# STM32H503 register map
File version: 1.5
CPU: CM33 r0p0, little endian, MPU, FPU, 4 interrupt priority bits
Registers are 32-bit, read-write, reset 0x0 unless marked. A register's access mark holds for its fields unless they carry their own. Offsets are from the block's base; [hi:lo] are bit positions; 'fields as' and 'values as' point back to an identical list.

## FLASH — FLASH address block description
Base 0x40022000
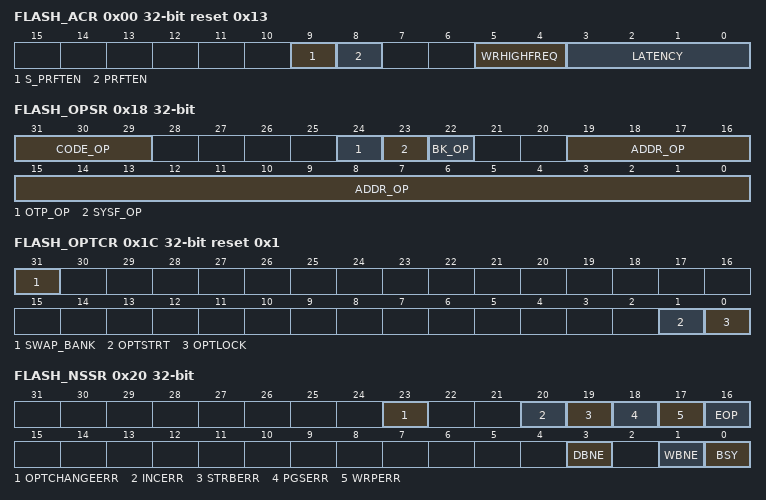
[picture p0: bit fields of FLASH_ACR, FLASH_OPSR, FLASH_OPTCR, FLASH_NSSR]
0x00 FLASH_ACR reset 0x13 — FLASH access control register
  [9] S_PRFTEN — Smart prefetch enable. When bit value is modified, user must read back ACR register to be sure S_PRFTEN has been taken into account. Bits used to control the prefetch functionality.
    0=prefetch, if enabled fetches each instruction; 1=prefetch, if enabled avoids fetch past branch to improve efficiency
  [8] PRFTEN — Prefetch enable. When bit value is modified, user must read back ACR register to be sure PRFTEN has been taken into account. Bits used to control the prefetch.
    0=prefetch disabled; 1=prefetch enabled when latency is at least one wait state
  [5:4] WRHIGHFREQ — Flash signal delay These bits are used to control the delay between non-volatile memory signals during programming operations. Application software has to program them to the correct value depending on the embedded Flash memory interface frequency. Please refer to for details. Note: No check is performed to verify that the configuration is correct. Two WRHIGHFREQ values can be selected for some frequencies.
  [3:0] LATENCY — Read latency These bits are used to control the number of wait states used during read operations on both non-volatile memory banks. The application software has to program them to the correct value depending on the embedded Flash memory interface frequency and voltage conditions. ... Note: No check is performed by hardware to verify that the configuration is correct.
    0=zero wait state used to read a word from non-volatile memory; 1=one wait state used to read a word from non-volatile memory; 2=two wait states used to read a word from non-volatile memory; 7=seven wait states used to read a word from non-volatile memory; 15=15 wait states used to read from non-volatile memory
0x04 FLASH_NSKEYR wo — FLASH key register
  [31:0] NSKEY — Non-volatile memory configuration access unlock key
0x0C FLASH_OPTKEYR wo — FLASH option key register
  [31:0] OPTKEY — FLASH option bytes control access unlock key
0x18 FLASH_OPSR ro reset not defined — FLASH operation status register
  [31:29] CODE_OP — Flash memory operation code
    0=No Flash operation on going during previous reset; 1=Single write operation interrupted; 3=Sector erase operation interrupted; 4=Bank erase operation interrupted; 5=Mass erase operation interrupted; 6=Option change operation interrupted
  [24] OTP_OP — OTP operation interrupted Indicates that reset interrupted an ongoing operation in OTP area.
  [23] SYSF_OP — Operation in system Flash memory interrupted Indicates that reset interrupted an ongoing operation in System Flash.
  [22] BK_OP — Interrupted operation bank It indicates which bank was concerned by operation.
  [19:0] ADDR_OP — Interrupted operation address.
0x1C FLASH_OPTCR access per field reset 0x1 (reset mask 0xFFFFFFF) — FLASH option control register
  [31] SWAP_BANK ro — Bank swapping option configuration bit SWAP_BANK controls whether Bank1 and Bank2 are swapped or not. This bit is loaded with the SWAP_BANK bit of FLASH_OPTSR_CUR register only after reset or POR.
    0=Bank1 and Bank2 not swapped; 1=Bank1 and Bank2 swapped
  [1] OPTSTRT rw — Option byte start change option configuration bit OPTSTRT triggers an option byte change operation. The user can set OPTSTRT only when the OPTLOCK bit is cleared to 0. It's set only by Software and cleared when the option byte change is completed or an error occurs (PGSERR or OPTCHANGEERR). It's reseted at the same time as BSY bit. The user application cannot modify any FLASH_XXX_PRG embedded Flash memory register until the option change operation has been completed. Before setting this bit, the user has to write the required values in the FLASH_XXX_PRG registers. The FLASH_XXX_PRG registers are locked until the option byte change operation has been executed in non-volatile memory.
  [0] OPTLOCK rw — FLASH_OPTCR lock option configuration bit The OPTLOCK bit locks the FLASH_OPTCR register as well as all _PRG registers. The correct write sequence to FLASH_OPTKEYR register unlocks this bit. If a wrong sequence is executed, or the unlock sequence to FLASH_OPTKEYR is performed twice, this bit remains locked until next system reset. It is possible to set OPTLOCK by programming it to 1. When set to 1, a new unlock sequence is mandatory to unlock it. When OPTLOCK changes from 0 to 1, the others bits of FLASH_OPTCR register do not change.
    0=FLASH_OPTCR register unlocked; 1=FLASH_OPTCR register locked
0x20 FLASH_NSSR ro (reset mask 0xFFFFFFF0) — FLASH non-secure status register
  [23] OPTCHANGEERR — Option byte change error flag OPTCHANGEERR flag indicates that an error occurred during an option byte change operation. When OPTCHANGEERR is set to 1, the option byte change operation did not successfully complete. An interrupt is generated when this flag is raised if the OPTCHANGEERRIE bit of FLASH_NSCR register is set to 1. Writing 1 to CLR_OPTCHANGEERR of register FLASH_CCR clears OPTCHANGEERR. Note: The OPTSTRT bit in FLASH_OPTCR cannot be set while OPTCHANGEERR is set.
    0=no option byte change errors occurred; 1=one or more errors occurred during an option byte change operation
  [20] INCERR — inconsistency error flag INCERR flag is raised when a inconsistency error occurs. An interrupt is generated if INCERRIE is set to 1. Writing 1 to CLR_INCERR bit in the FLASH_NSCCR register clears INCERR.
    0=no inconsistency error occurs; 1=a inconsistency error occurs
  [19] STRBERR — strobe error flag STRBERR flag is raised when a strobe error occurs (when the master attempts to write several times the same byte in the write buffer). An interrupt is generated if the STRBERRIE bit is set to 1. Writing 1 to CLR_STRBERR bit in FLASH_NSCCR register clears STRBERR.
    0=no strobe error occurred; 1=a strobe error occurred
  [18] PGSERR — programming sequence error flag PGSERR flag is raised when a sequence error occurs. An interrupt is generated if the PGSERRIE bit is set to 1. Writing 1 to CLR_PGSERR bit in FLASH_NSCCR register clears PGSERR.
    0=no sequence error occurred; 1=a sequence error occurred
  [17] WRPERR — write protection error flag WRPERR flag is raised when a protection error occurs during a program operation. An interrupt is also generated if the WRPERRIE is set to 1. Writing 1 to CLR_WRPERR bit in FLASH_NSCCR register clears WRPERR.
    0=no write protection error occurred; 1=a write protection error occurred
  [16] EOP — end of operation flag EOP flag is set when a operation (program/erase) completes. An interrupt is generated if the EOPIE is set to 1. It is not necessary to reset EOP before starting a new operation. EOP bit is cleared by writing 1 to CLR_EOP bit in FLASH_NSCCR register.
    0=no operation completed; 1=a operation completed
  [3] DBNE — data buffer not empty flag DBNE flag is set when the embedded Flash memory interface is processing 6-bits ECC data in dedicated buffer. This bit cannot be set to 0 by software. The hardware resets it once the buffer is free.
    0=data buffer not used; 1=data buffer used, wait
  [1] WBNE — write buffer not empty flag WBNE flag is set when the embedded Flash memory is waiting for new data to complete the write buffer. In this state, the write buffer is not empty. WBNE is reset by hardware each time the write buffer is complete or the write buffer is emptied following one of the event below: the application software forces the write operation using FW bit in FLASH_NSCR the embedded Flash memory detects an error that involves data loss This bit cannot be reset by software writing 0 directly. To reset it, clear the write buffer by performing any of the above listed actions, or send the missing data.
    0=write buffer empty or full; 1=write buffer waiting data to complete
  [0] BSY — busy flag BSY flag indicates that a Flash memory is busy by an operation (write, erase, option byte change). It is set at the beginning of a Flash memory operation and cleared when the operation finishes or an error occurs.
    0=no programming, erase or option byte change operation being executed; 1=programming, erase or option byte change operation being executed
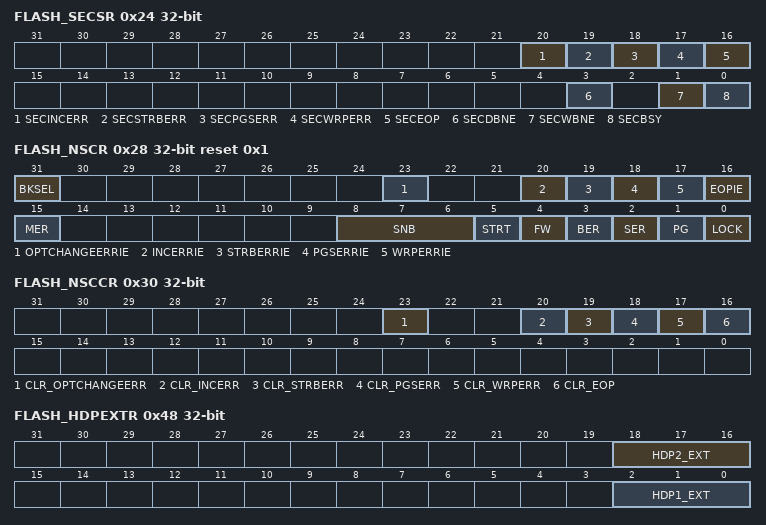
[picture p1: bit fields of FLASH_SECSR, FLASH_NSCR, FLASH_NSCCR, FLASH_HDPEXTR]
0x24 FLASH_SECSR ro (reset mask 0xFFFFFFF0) — FLASH secure status register
  [20] SECINCERR — inconsistency error flag INCERR flag is raised when a inconsistency error occurs. An interrupt is generated if INCERRIE is set to 1. Writing 1 to CLR_INCERR bit in the FLASH_SECCCR register clears INCERR.
    0=no inconsistency error occurred; 1=a inconsistency error occurred
  [19] SECSTRBERR — strobe error flag STRBERR flag is raised when a strobe error occurs (when the master attempts to write several times the same byte in the write buffer). An interrupt is generated if the STRBERRIE bit is set to 1. Writing 1 to CLR_STRBERR bit in FLASH_SECCCR register clears STRBERR.
    0=no strobe error occurred; 1=a strobe error occurred
  [18] SECPGSERR — programming sequence error flag PGSERR flag is raised when a sequence error occurs. An interrupt is generated if the PGSERRIE bit is set to 1. Writing 1 to CLR_PGSERR bit in FLASH_SECCCR register clears PGSERR.
    0=no sequence error occurred; 1=a sequence error occurred
  [17] SECWRPERR — write protection error flag WRPERR flag is raised when a protection error occurs during a program operation. An interrupt is also generated if the WRPERRIE is set to 1. Writing 1 to CLR_WRPERR bit in FLASH_SECCCR register clears WRPERR.
    values as FLASH_NSSR.WRPERR
  [16] SECEOP — end of operation flag EOP flag is set when a operation (program/erase) completes. An interrupt is generated if the EOPIE is set to. It is not necessary to reset EOP before starting a new operation. EOP bit is cleared by writing 1 to CLR_EOP bit in FLASH_SECCCR register.
    0=no operation completed; 1=a operation completed
  [3] SECDBNE — data buffer not empty flag DBNE flag is set when the embedded Flash memory interface is processing 6-bits ECC data in dedicated buffer. This bit cannot be set to 0 by software. The hardware resets it once the buffer is free.
    0=data buffer not used; 1=data buffer used, wait
  [1] SECWBNE — write buffer not empty flag WBNE flag is set when the embedded Flash memory is waiting for new data to complete the write buffer. In this state, the write buffer is not empty. WBNE is reset by hardware each time the write buffer is complete or the write buffer is emptied following one of the event below: the application software forces the write operation using FW bit in FLASH_SECCR the embedded Flash memory detects an error that involves data loss This bit cannot be reset by writing 0 directly by software. To reset it, clear the write buffer by performing any of the above listed actions, or send the missing data.
    values as FLASH_NSSR.WBNE
  [0] SECBSY — busy flag BSY flag indicates that a FLASH memory is busy by an operation (write, erase, option byte change, OBK operations, PUF operation). It is set at the beginning of a Flash memory operation and cleared when the operation finishes or an error occurs.
    values as FLASH_NSSR.BSY
0x28 FLASH_NSCR reset 0x1 — FLASH Non Secure control register
  [31] BKSEL — Bank selector bit BKSEL can only be programmed when LOCK is cleared to 0. The bit selects physical bank, SWAP_BANK setting is ignored.
    0=Bank1 is selected for Bank erase / sector erase / interrupt enable; 1=Bank2 is selected for BER / SER
  [23] OPTCHANGEERRIE — Option byte change error interrupt enable bit OPTCHANGEERRIE bit controls if an interrupt has to be generated when an error occurs during an option byte change. This bit can be programmed only when LOCK bit is cleared to 0.
    0=no interrupt is generated when an error occurs during an option byte change; 1=an interrupt is generated when and error occurs during an option byte change
  [20] INCERRIE — inconsistency error interrupt enable bit When INCERRIE bit is set to 1, an interrupt is generated when an inconsistency error occurs during a write operation. INCERRIE can be programmed only when LOCK is cleared to 0.
    0=no interrupt generated when a inconsistency error occurs; 1=interrupt generated when a inconsistency error occurs
  [19] STRBERRIE — strobe error interrupt enable bit When STRBERRIE bit is set to 1, an interrupt is generated when a strobe error occurs (the master programs several times the same byte in the write buffer) during a write operation. STRBERRIE can be programmed only when LOCK is cleared to 0.
    0=no interrupt generated when a strobe error occurs; 1=interrupt generated when strobe error occurs
  [18] PGSERRIE — programming sequence error interrupt enable bit When PGSERRIE bit is set to 1, an interrupt is generated when a sequence error occurs during a program operation. PGSERRIE can be programmed only when LOCK is cleared to 0.
    0=no interrupt generated when a sequence error occurs; 1=interrupt generated when sequence error occurs
  [17] WRPERRIE — write protection error interrupt enable bit When WRPERRIE bit is set to 1, an interrupt is generated when a protection error occurs during a program operation. WRPERRIE can be programmed only when LOCK is cleared to 0.
    0=no interrupt generated when a protection error occurs; 1=interrupt generated when a protection error occurs
  [16] EOPIE — end of operation interrupt control bit Setting EOPIE bit to 1 enables the generation of an interrupt at the end of a program or erase operation. EOPIE can be programmed only when LOCK is cleared to 0.
    0=no interrupt generated at the end of operation; 1=interrupt enabled when at the end of operation
  [15] MER — Mass erase request Setting MER bit to 1 requests a mass erase operation (user Flash memory only). MER can be programmed only when LOCK is cleared to 0. If BER or SER are both set, a PGSERR is raised. Error is triggered when a mass erase is required and some sectors are protected.
    0=mass erase not requested; 1=mass erase requested
  [8:6] SNB — sector erase selection number These bits are used to select the target sector for an erase operation (they are unused otherwise). SNB can be programmed only when LOCK is cleared to 0. ...
    0=Sector 0 selected; 1=Sector 1 selected; 7=Sector 7 selected
  [5] STRT — erase start control bit STRT bit is used to start a sector erase or a bank erase operation. STRT can be programmed only when LOCK is cleared to 0. STRT is reset at the end of the operation or when an error occurs. It cannot be reseted by software.
  [4] FW — write forcing control bit FW forces a write operation even if the write buffer is not full. In this case all bits not written are set to 1 by hardware. FW can be programmed only when LOCK is cleared to 0. The embedded Flash memory resets FW when the corresponding operation has been acknowledged. Note: Using a force-write operation prevents the application from updating later the missing bits with something else than 1, because it is likely that it leads to permanent ECC error. Write forcing is effective only if the write buffer is not empty (in particular, FW does not start several write operations when the force-write operations are performed consecutively). Since there is just one write buffer, FW can force a write in bank1 or bank2.
  [3] BER — erase request Setting BER bit to 1 requests a bank erase operation (user Flash memory only). BER can be programmed only when LOCK is cleared to 0. If MER and SER are also set, a PGSERR is raised. Note: Write protection error is triggered when a bank erase is required and some sectors are protected.
    0=bank erase not requested; 1=bank erase requested
  [2] SER — sector erase request Setting SER bit to 1 requests a sector erase. SER can be programmed only when LOCK is cleared to 0. If MER and SER are also set, a PGSERR is raised.
    0=sector erase not requested; 1=sector erase requested
  [1] PG — programming control bit PG can be programmed only when LOCK is cleared to 0. PG allows programming in Bank1 and Bank2.
    0=programming disabled; 1=programming enabled
  [0] LOCK — configuration lock bit This bit locks the FLASH_NSCR register. The correct write sequence to FLASH_NSKEYR register unlocks this bit. If a wrong sequence is executed, or if the unlock sequence to FLASH_NSKEYR is performed twice, this bit remains locked until the next system reset. LOCK can be set by programming it to 1. When set to 1, a new unlock sequence is mandatory to unlock it. When LOCK changes from 0 to 1, the other bits of FLASH_NSCR register do not change.
    0=FLASH_NSCR register unlocked; 1=FLASH_NSCR register locked
0x30 FLASH_NSCCR wo — FLASH non-secure clear control register
  [23] CLR_OPTCHANGEERR — Clear the flag corresponding flag in FLASH_NSSR by writing this bit.
  [20] CLR_INCERR — INCERR flag clear bit Setting this bit to 1 resets to 0 INCERR flag in FLASH_NSSR register.
  [19] CLR_STRBERR — STRBERR flag clear bit Setting this bit to 1 resets to 0 STRBERR flag in FLASH_NSSR register.
  [18] CLR_PGSERR — PGSERR flag clear bit Setting this bit to 1 resets to 0 PGSERR flag in FLASH_NSSR register.
  [17] CLR_WRPERR — WRPERR flag clear bit Setting this bit to 1 resets to 0 WRPERR flag in FLASH_NSSR register.
  [16] CLR_EOP — EOP flag clear bit Setting this bit to 1 resets to 0 EOP flag in FLASH_NSSR register.
0x3C FLASH_PRIVCFGR wo — FLASH privilege configuration register
  [1] NSPRIV — privilege attribute for non secure registers
    0=access to non secure registers is always granted; 1=access to non secure registers is denied in case of non privileged access
0x48 FLASH_HDPEXTR — FLASH HDP extension register
  [18:16] HDP2_EXT — HDP area extension in 8 Kbytes sectors in Bank2. Extension is added after the HDP2_END sector.
  [2:0] HDP1_EXT — HDP area extension in 8 Kbytes sectors in Bank1. Extension is added after the HDP1_END sector.
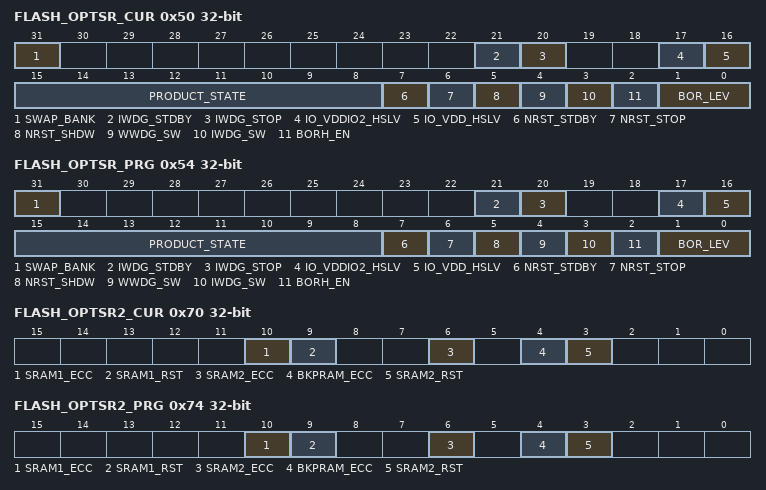
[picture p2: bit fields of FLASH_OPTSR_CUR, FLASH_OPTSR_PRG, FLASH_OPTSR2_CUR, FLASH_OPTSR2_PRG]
0x50 FLASH_OPTSR_CUR ro reset not defined — FLASH option status register
  [31] SWAP_BANK — Bank swapping option status bit SWAP_BANK reflects whether Bank1 and Bank2 are swapped or not. SWAP_BANK is loaded to SWAP_BANK of FLASH_OPTCR after a reset.
    0=Bank1 and Bank2 not swapped; 1=Bank1 and Bank2 swapped
  [21] IWDG_STDBY — IWDG Standby mode freeze option status bit When set the independent watchdog IWDG is frozen in system Standby mode.
    0=Independent watchdog frozen in Standby mode; 1=Independent watchdog keep running in Standby mode
  [20] IWDG_STOP — IWDG Stop mode freeze option status bit When set the independent watchdog IWDG is in system Stop mode.
    0=Independent watchdog frozen in system Stop mode; 1=Independent watchdog keep running in system Stop mode
  [17] IO_VDDIO2_HSLV — High-speed IO at low VDDIO2 voltage status bit. This bit can be set only with VDDIO2 below 2.5 V.
    0=High-speed IO at low VDDIO2 voltage feature disabled (VDDIO2 can exceed 2.5 V); 1=High-speed IO at low VDDIO2 voltage feature enabled (VDDIO2 remains below 2.5 V)
  [16] IO_VDD_HSLV — High-speed IO at low VDD voltage status bit. This bit can be set only with VDD below 2.5 V.
    0=High-speed IO at low VDD voltage feature disabled (VDD can exceed 2.5 V); 1=High-speed IO at low VDD voltage feature enabled (VDD remains below 2.5 V)
  [15:8] PRODUCT_STATE — Life state code (based on Hamming 8,4). More information in .
  [7] NRST_STDBY — Core domain Standby entry reset option status bit
    0=a reset is generated when entering Standby mode on core domain; 1=no reset generated when entering Standby mode on core domain
  [6] NRST_STOP — Core domain Stop entry reset option status bit
    0=a reset is generated when entering Stop mode on core domain; 1=no reset generated when entering Stop mode on core domain
  [5] NRST_SHDW — Core domain Shutdown entry reset option status bit
    0=a reset is generated when entering Shutdown mode on core domain; 1=no reset generated when entering Shutdown mode on core domain
  [4] WWDG_SW — WWDG control mode option status bit
    0=WWDG watchdog is controlled by hardware; 1=WWDG watchdog is controlled by software
  [3] IWDG_SW — IWDG control mode option status bit
    0=IWDG watchdog is controlled by hardware; 1=IWDG watchdog is controlled by software
  [2] BORH_EN — Brownout high enable status bit
    0=disabled; 1=enabled
  [1:0] BOR_LEV — Brownout level option status bit These bits reflects the power level that generates a system reset.
    0=BOR OFF, POR/PDR reset threshold level is applied; 1=BOR Level 1, the threshold level is low (around 2.1 V); 2=BOR Level 2, the threshold level is medium (around 2.4 V); 3=BOR Level 3, the threshold level is high (around 2.7 V)
0x54 FLASH_OPTSR_PRG reset not defined — FLASH option status register
  [31] SWAP_BANK — Bank swapping option configuration bit SWAP_BANK option bit is used to configure whether the Bank1 and Bank2 are swapped or not. This bit is loaded with the SWAP_BANK bit of FLASH_OPTSR_CUR register after a reset.
    0=Bank1 and Bank2 not swapped; 1=Bank1 and Bank2 swapped
  [21] IWDG_STDBY — IWDG Standby mode freeze option configuration bit When set the independent watchdog IWDG is frozen in system Standby mode.
    values as FLASH_OPTSR_CUR.IWDG_STDBY
  [20] IWDG_STOP — IWDG Stop mode freeze option configuration bit When set the independent watchdog IWDG is in system Stop mode.
    values as FLASH_OPTSR_CUR.IWDG_STOP
  [17] IO_VDDIO2_HSLV — High-speed IO at low VDDIO2 voltage configuration bit. This bit can be set only with VDDIO2 below 2.5 V.
    values as FLASH_OPTSR_CUR.IO_VDDIO2_HSLV
  [16] IO_VDD_HSLV — High-speed IO at low VDD voltage configuration bit. This bit can be set only with VDD below 2.5 V.
    values as FLASH_OPTSR_CUR.IO_VDD_HSLV
  [15:8] PRODUCT_STATE — Life state code (based on Hamming 8,4). More information in .
  [7] NRST_STDBY — Core domain Standby entry reset option configuration bit
    values as FLASH_OPTSR_CUR.NRST_STDBY
  [6] NRST_STOP — Core domain Stop entry reset option configuration bit
    values as FLASH_OPTSR_CUR.NRST_STOP
  [5] NRST_SHDW — Core domain Shutdown entry reset option configuration bit
    values as FLASH_OPTSR_CUR.NRST_SHDW
  [4] WWDG_SW — WWDG control mode option configuration bit
    values as FLASH_OPTSR_CUR.WWDG_SW
  [3] IWDG_SW — IWDG control mode option configuration bit
    values as FLASH_OPTSR_CUR.IWDG_SW
  [2] BORH_EN — Brownout high enable configuration bit
    0=disabled; 1=enabled
  [1:0] BOR_LEV — Brownout level option configuration bit These bits reflects the power level that generates a system reset.
    values as FLASH_OPTSR_CUR.BOR_LEV
0x70 FLASH_OPTSR2_CUR ro reset not defined — FLASH option status register 2
  [10] SRAM1_ECC — SRAM1 ECC detection and correction disable
    0=SRAM1 ECC check enabled; 1=SRAM1 ECC check disabled
  [9] SRAM1_RST — SRAM1 erase upon system reset
    0=SRAM1 erased when a system reset occurs; 1=SRAM1 not erased when a system reset occurs
  [6] SRAM2_ECC — SRAM2 ECC detection and correction disable
    0=SRAM2 ECC check enabled; 1=SRAM2 ECC check disabled
  [4] BKPRAM_ECC — Backup RAM ECC detection and correction disable
    0=BKPRAM ECC check enabled; 1=BKPRAM ECC check disabled
  [3] SRAM2_RST — SRAM2 erase when system reset
    0=SRAM2 erased when a system reset occurs; 1=SRAM2 not erased when a system reset occurs
0x74 FLASH_OPTSR2_PRG reset not defined — FLASH option status register 2
  fields as FLASH_OPTSR2_CUR
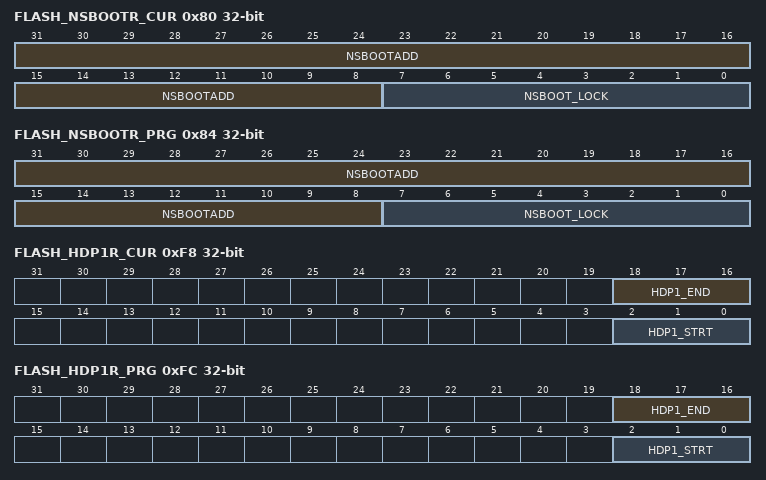
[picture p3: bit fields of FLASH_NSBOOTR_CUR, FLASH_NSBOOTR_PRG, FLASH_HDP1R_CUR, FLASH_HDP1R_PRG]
0x80 FLASH_NSBOOTR_CUR ro reset not defined — FLASH non-secure unique boot entry register
  [31:8] NSBOOTADD — unique boot entry address These bits reflect the UBE address
  [7:0] NSBOOT_LOCK — A field locking the values of SWAP_BANK, and NSBOOTADD settings.
    195=The SWAP_BANK and NSBOOTADD can still be modified following their individual rules; 180=The NSBOOTADD and SWAP_BANK are frozen
0x84 FLASH_NSBOOTR_PRG reset not defined — FLASH non-secure unique boot entry address
  [31:8] NSBOOTADD — Unique boot entry address These bits allow configuring the BOOT address
  [7:0] NSBOOT_LOCK — A field locking the values of SWAP_BANK, and NSBOOTADD settings.
    values as FLASH_NSBOOTR_CUR.NSBOOT_LOCK
0x90 FLASH_OTPBLR_CUR ro reset not defined — FLASH non-secure OTP block lock
  [31:0] LOCKBL — OTP block lock Block n corresponds to OTP 16-bit word 32 x n to 32 x n + 31. LOCKBL[n] = 1 indicates that all OTP 16-bit words in OTP Block n are locked and attempt to program them results in WRPERR. LOCKBL[n] = 0 indicates that all OTP 16-bit words in OTP Block n are not locked. When one block is locked, it's not possible to remove the write protection. Also if not locked, it is not possible to erase OTP words.
0x94 FLASH_OTPBLR_PRG reset not defined — FLASH non-secure OTP block lock
  [31:0] LOCKBL — OTP block lock Block n corresponds to OTP 16-bit word 32 x n to 32 x n + 31. LOCKBL[n] = 1 indicates that all OTP 16-bit words in OTP Block n are locked and attempt to program them results in WRPERR. LOCKBL[n] = 0 indicates that all OTP 16-bit words in OTP Block n are not locked. When one block is locked, it is not possible to remove the write protection. LOCKBL bits can be set if the corresponding bit in FLASH_OTPBLR_CUR is cleared.
0xC0 FLASH_PRIVBB1R — FLASH privilege register for bank 1
  [7:0] PRIVBB1 — Privileged / unprivileged 8 Kbytes Flash Bank1 sector attribute (y = 0 to 7)
    0=sectors y in bank 1 is non privileged; 1=sector y in bank 1 is privileged
0xE8 FLASH_WRPSGN1R_CUR ro reset not defined — FLASH write sector protection for Bank1
  [7:0] WRPSG1 — Bank1 sector protection option status byte Setting WRPSG1 bits to 0 write protects the corresponding sectors in bank 1 (0: write protected; 1: not write protected)
0xEC FLASH_WRPSGN1R_PRG reset not defined — FLASH write sector protection for Bank1
  fields as FLASH_WRPSGN1R_CUR
0xF8 FLASH_HDP1R_CUR ro reset not defined — FLASH HDP Bank1 register
  [18:16] HDP1_END — HDPL barrier end set in number of 8 Kbytes sectors
  [2:0] HDP1_STRT — HDPL barrier start set in number of 8 Kbytes sectors
0xFC FLASH_HDP1R_PRG ro reset not defined — FLASH HDP Bank1 register
  [18:16] HDP1_END — Bank 1 HDPL barrier end set in number of 8 Kbytes sectors
  [2:0] HDP1_STRT — Bank 1 HDPL barrier start set in number of 8 Kbytes sectors
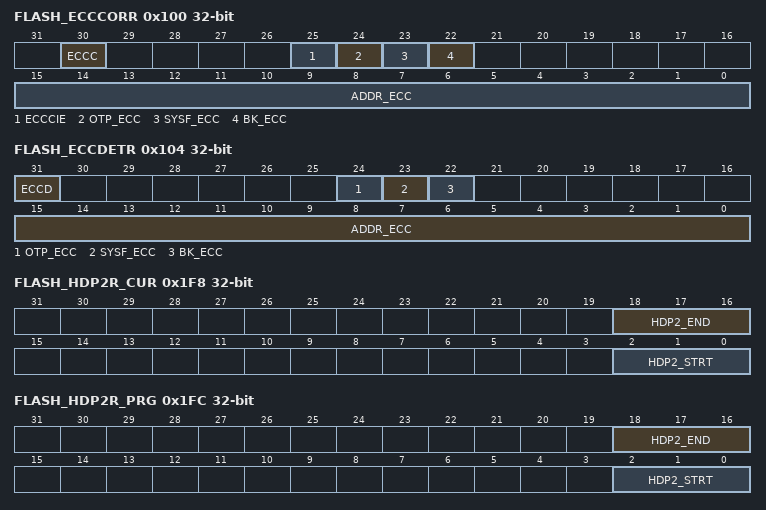
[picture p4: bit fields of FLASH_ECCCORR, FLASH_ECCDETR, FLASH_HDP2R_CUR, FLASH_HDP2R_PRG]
0x100 FLASH_ECCCORR access per field — FLASH Flash ECC correction register
  [30] ECCC rw — ECC correction set by hardware when single ECC error has been detected and corrected. Cleared by writing 1.
  [25] ECCCIE rw — ECC single correction error interrupt enable bit When ECCCIE bit is set to 1, an interrupt is generated when an ECC single correction error occurs during a read operation.
    0=no interrupt generated when an ECC single correction error occurs; 1=non-secure interrupt generated when an ECC single correction error occurs
  [24] OTP_ECC ro — OTP ECC error bit This bit is set to 1 when one single ECC correction occurred during the last successful read operation from the read-only/ OTP area. The address of the ECC error is available in ADDR_ECC bitfield.
  [23] SYSF_ECC ro — ECC flag for corrected ECC error in system FLASH It indicates if system Flash memory is concerned by ECC error.
  [22] BK_ECC ro — ECC bank flag for corrected ECC error It indicates which bank is concerned by ECC error
  [15:0] ADDR_ECC ro — ECC error address When an ECC error occurs (for single correction) during a read operation, the ADDR_ECC contains the address that generated the error. ADDR_ECC is reset when the flag error is reset. The embedded Flash memory programs the address in this register only when no ECC error flags are set. This means that only the first address that generated an ECC error is saved. The address in ADDR_ECC is relative to the Flash memory area where the error occurred (user Flash memory, system Flash memory, data area, read-only/OTP area).
0x104 FLASH_ECCDETR access per field — FLASH ECC detection register
  [31] ECCD rw — ECC detection set by hardware when two ECC error has been detected. When this bit is set, a NMI is generated. Cleared by writing 1. Needs to be cleared in order to detect subsequent double ECC errors.
  [24] OTP_ECC ro — OTP ECC error bit This bit is set to 1 when double ECC detection occurred during the last read operation from the read-only/ OTP area. The address of the ECC error is available in ADDR_ECC bit field.
  [23] SYSF_ECC ro — ECC fail for double ECC error in system Flash memory It indicates if system Flash memory is concerned by ECC error.
  [22] BK_ECC ro — ECC fail bank for double ECC Error It indicates which bank is concerned by ECC error
  [15:0] ADDR_ECC ro — ECC error address When an ECC error occurs (double detection) during a read operation, the ADDR_ECC contains the address that generated the error. ADDR_ECC is reset when the flag error is reset. The embedded Flash memory programs the address in this register only when no ECC error flags are set. This means that only the first address that generated an double ECC error is saved. The address in ADDR_ECC is relative to the Flash memory area where the error occurred (user Flash memory, system Flash memory, data area, read-only/OTP area).
0x108 FLASH_ECCDR ro — FLASH ECC data
  [15:0] DATA_ECC — ECC error data When an double detection ECC error occurs on special areas with 6-bit ECC on 16-bit of data (data area, read-only/OTP area), the failing data is read to this register. By checking if it is possible to determine whether the failure was on a real data, or due to access to uninitialized memory.
0x1E8 FLASH_WRPSGN2R_CUR ro reset not defined — FLASH write sector protection for Bank2
  [7:0] WRPSG2 — Bank2 sector protection option status byte Setting WRPSG2 bits to 0 write protects the corresponding sectors in bank 2 (0: write protected; 1: not write protected)
0x1EC FLASH_WRPSGN2R_PRG reset not defined — FLASH write sector protection for Bank2
  fields as FLASH_WRPSGN2R_CUR
0x1F8 FLASH_HDP2R_CUR ro reset not defined — FLASH HDP Bank2 register
  [18:16] HDP2_END — Bank 2 HDPL barrier end set in number of 8 Kbytes sectors
  [2:0] HDP2_STRT — Bank 2 HDPL barrier start set in number of 8 Kbytes sectors
0x1FC FLASH_HDP2R_PRG reset not defined — FLASH HDP Bank2 register
  fields as FLASH_HDP2R_CUR
